# MB9BF12xT register map
File version: 1.0
CPU: 
Registers are 8-bit, read-write, reset 0x0 unless marked. A register's access mark holds for its fields unless they carry their own. Offsets are from the block's base; [hi:lo] are bit positions; {n}, {i} and the like mark numbered series.

## HDMICEC0 — peripheral HDMICEC0
Base 0x40034000
Same registers: HDMICEC1 0x40034100
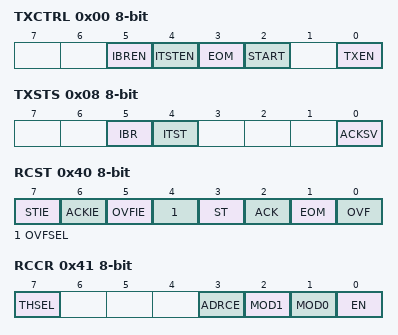
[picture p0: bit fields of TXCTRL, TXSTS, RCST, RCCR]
0x00 TXCTRL
  [5] IBREN, [4] ITSTEN, [3] EOM, [2] START, [0] TXEN
0x04 TXDATA
0x08 TXSTS
  [5] IBR, [4] ITST, [0] ACKSV
0x0C SFREE
  [3:0] SFREE
0x40 RCST
  [7] STIE, [6] ACKIE, [5] OVFIE, [4] OVFSEL, [3] ST, [2] ACK, [1] EOM, [0] OVF
0x41 RCCR
  [7] THSEL, [3] ADRCE, [2] MOD1, [1] MOD0, [0] EN
0x44 RCDAHW
0x45 RCSHW
0x49 RCDBHW
0x4C RCADR2
  [4:0] RCADR2
0x4D RCADR1
  [4:0] RCADR1
0x50 RCDTHL ro
0x51 RCDTHH ro
0x54 RCDTLL ro
0x55 RCDTLH ro
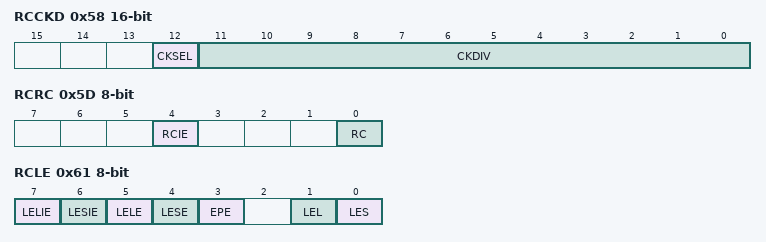
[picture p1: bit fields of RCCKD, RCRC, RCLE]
0x58 RCCKD 16-bit
  [12] CKSEL, [11:0] CKDIV
0x5C RCRHW
0x5D RCRC
  [4] RCIE, [0] RC
0x61 RCLE
  [7] LELIE, [6] LESIE, [5] LELE, [4] LESE, [3] EPE, [1] LEL, [0] LES
0x64 RCLESW
0x65 RCLELW

## LVD — peripheral LVD
Base 0x40035000
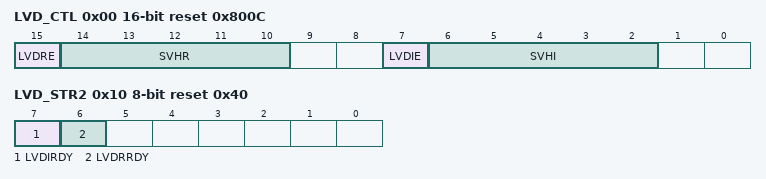
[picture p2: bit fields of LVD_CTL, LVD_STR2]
0x00 LVD_CTL 16-bit reset 0x800C
  [15] LVDRE, [14:10] SVHR, [7] LVDIE, [6:2] SVHI
0x04 LVD_STR ro
  [7] LVDIR
0x08 LVD_CLR reset 0x80
  [7] LVDCL
0x0C LVD_RLR 32-bit reset 0x1
  [31:0] LVDLCK
0x10 LVD_STR2 ro reset 0x40
  [7] LVDIRDY, [6] LVDRRDY

## DS — peripheral DS
Base 0x40035100
0x00 REG_CTL reset 0x4
  [2:1] ISUBSEL
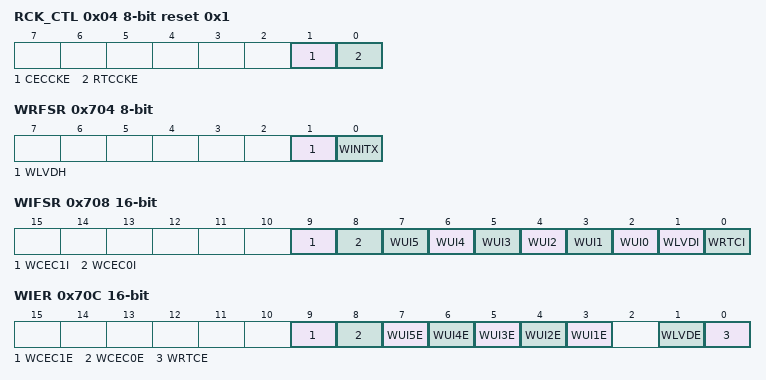
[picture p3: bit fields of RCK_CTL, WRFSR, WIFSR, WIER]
0x04 RCK_CTL reset 0x1
  [1] CECCKE, [0] RTCCKE
0x700 PMD_CTL
  [0] RTCE
0x704 WRFSR
  [1] WLVDH, [0] WINITX
0x708 WIFSR 16-bit ro
  [9] WCEC1I, [8] WCEC0I, [n+2] WUI{n} (n=0..5), [1] WLVDI, [0] WRTCI
0x70C WIER 16-bit
  [9] WCEC1E, [8] WCEC0E, [n+2] WUI{n}E (n=1..5), [1] WLVDE, [0] WRTCE
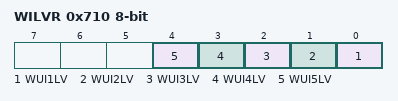
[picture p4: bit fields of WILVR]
0x710 WILVR
  [n-1] WUI{n}LV (n=1..5)
0x714 DSRAMR
  [1:0] SRAMR
{0x7FF+i} BUR{i:02} (i=1..16)

## MFS0 — peripheral MFS0
Base 0x40038000
Same registers: MFS{n} {0x40038000+0x100*n} (n=1..15)
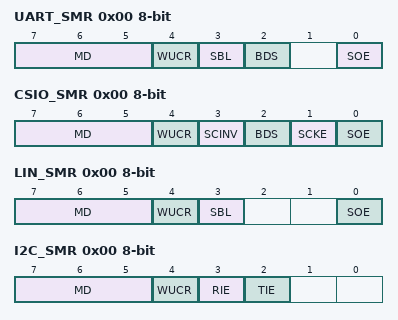
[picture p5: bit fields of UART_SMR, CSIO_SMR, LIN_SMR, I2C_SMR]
0x00 UART_SMR (UART view)
  [7:5] MD, [4] WUCR, [3] SBL, [2] BDS, [0] SOE
0x00 CSIO_SMR (CSIO view)
  [7:5] MD, [4] WUCR, [3] SCINV, [2] BDS, [1] SCKE, [0] SOE
0x00 LIN_SMR (LIN view)
  [7:5] MD, [4] WUCR, [3] SBL, [0] SOE
0x00 I2C_SMR (I2C view)
  [7:5] MD, [4] WUCR, [3] RIE, [2] TIE
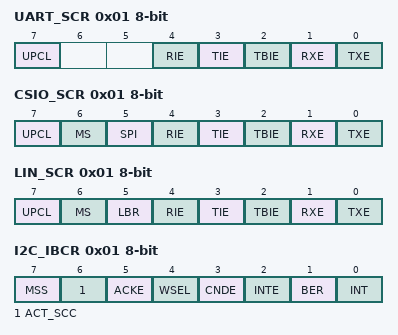
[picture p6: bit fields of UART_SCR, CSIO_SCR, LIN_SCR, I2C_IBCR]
0x01 UART_SCR (UART view)
  [7] UPCL, [4] RIE, [3] TIE, [2] TBIE, [1] RXE, [0] TXE
0x01 CSIO_SCR (CSIO view)
  [7] UPCL, [6] MS, [5] SPI, [4] RIE, [3] TIE, [2] TBIE, [1] RXE, [0] TXE
0x01 LIN_SCR (LIN view)
  [7] UPCL, [6] MS, [5] LBR, [4] RIE, [3] TIE, [2] TBIE, [1] RXE, [0] TXE
0x01 I2C_IBCR (I2C view)
  [7] MSS, [6] ACT_SCC, [5] ACKE, [4] WSEL, [3] CNDE, [2] INTE, [1] BER ro, [0] INT
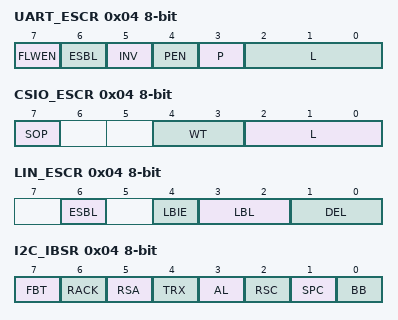
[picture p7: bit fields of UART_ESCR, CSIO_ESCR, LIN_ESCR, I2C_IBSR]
0x04 UART_ESCR (UART view)
  [7] FLWEN, [6] ESBL, [5] INV, [4] PEN, [3] P, [2:0] L
0x04 CSIO_ESCR (CSIO view)
  [7] SOP, [4:3] WT, [2:0] L
0x04 LIN_ESCR (LIN view)
  [6] ESBL, [4] LBIE, [3:2] LBL, [1:0] DEL
0x04 I2C_IBSR (I2C view)
  [7] FBT ro, [6] RACK ro, [5] RSA ro, [4] TRX ro, [3] AL ro, [2] RSC, [1] SPC, [0] BB ro
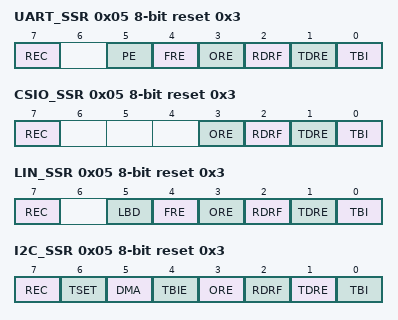
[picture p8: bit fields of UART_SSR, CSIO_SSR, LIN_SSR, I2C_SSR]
0x05 UART_SSR reset 0x3 (UART view)
  [7] REC, [5] PE ro, [4] FRE ro, [3] ORE ro, [2] RDRF ro, [1] TDRE ro, [0] TBI ro
0x05 CSIO_SSR reset 0x3 (CSIO view)
  [7] REC, [3] ORE ro, [2] RDRF ro, [1] TDRE ro, [0] TBI ro
0x05 LIN_SSR reset 0x3 (LIN view)
  [7] REC, [5] LBD, [4] FRE ro, [3] ORE ro, [2] RDRF ro, [1] TDRE ro, [0] TBI ro
0x05 I2C_SSR reset 0x3 (I2C view)
  [7] REC, [6] TSET, [5] DMA, [4] TBIE, [3] ORE ro, [2] RDRF ro, [1] TDRE ro, [0] TBI ro
0x08 UART_RDR 16-bit ro (reset mask 0x1FF) (UART view)
0x08 UART_TDR 16-bit wo reset 0x1FF (reset mask 0x1FF) (UART view)
0x08 CSIO_RDR 16-bit ro (reset mask 0x1FF) (CSIO view)
0x08 CSIO_TDR 16-bit wo reset 0x1FF (reset mask 0x1FF) (CSIO view)
0x08 LIN_RDR 16-bit ro (reset mask 0xFF) (LIN view)
0x08 LIN_TDR 16-bit wo reset 0xFF (reset mask 0xFF) (LIN view)
0x08 I2C_RDR 16-bit ro (reset mask 0xFF) (I2C view)
0x08 I2C_TDR 16-bit wo reset 0xFF (reset mask 0xFF) (I2C view)
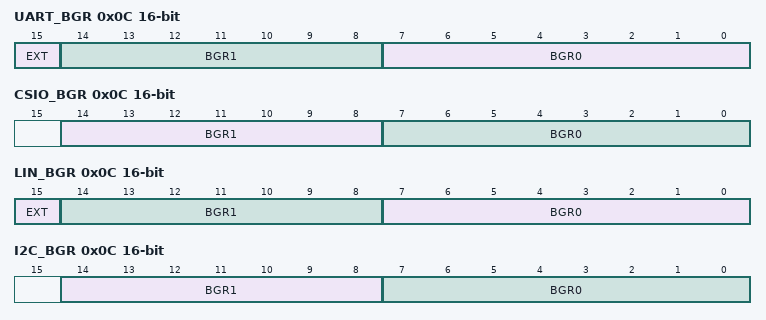
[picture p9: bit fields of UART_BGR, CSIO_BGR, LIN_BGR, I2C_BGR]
0x0C UART_BGR 16-bit (UART view)
  [15] EXT, [14:8] BGR1, [7:0] BGR0
0x0C CSIO_BGR 16-bit (CSIO view)
  [14:8] BGR1, [7:0] BGR0
0x0C LIN_BGR 16-bit (LIN view)
  [15] EXT, [14:8] BGR1, [7:0] BGR0
0x0C I2C_BGR 16-bit (I2C view)
  [14:8] BGR1, [7:0] BGR0
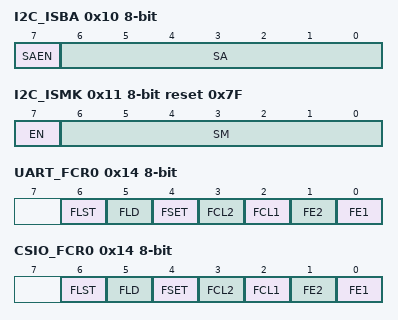
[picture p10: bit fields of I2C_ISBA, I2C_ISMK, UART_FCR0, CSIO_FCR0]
0x10 I2C_ISBA (I2C view)
  [7] SAEN, [6:0] SA
0x11 I2C_ISMK reset 0x7F (I2C view)
  [7] EN, [6:0] SM
0x14 UART_FCR0 (UART view)
  [6] FLST ro, [5] FLD, [4] FSET, [3] FCL2, [2] FCL1, [1] FE2, [0] FE1
0x14 CSIO_FCR0 (CSIO view)
  [6] FLST ro, [5] FLD, [4] FSET, [3] FCL2, [2] FCL1, [1] FE2, [0] FE1
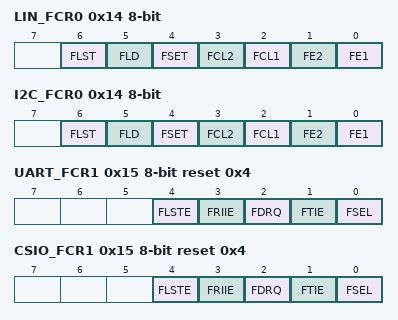
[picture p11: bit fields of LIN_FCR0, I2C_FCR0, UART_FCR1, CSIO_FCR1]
0x14 LIN_FCR0 (LIN view)
  [6] FLST ro, [5] FLD, [4] FSET, [3] FCL2, [2] FCL1, [1] FE2, [0] FE1
0x14 I2C_FCR0 (I2C view)
  [6] FLST ro, [5] FLD, [4] FSET, [3] FCL2, [2] FCL1, [1] FE2, [0] FE1
0x15 UART_FCR1 reset 0x4 (UART view)
  [4] FLSTE, [3] FRIIE, [2] FDRQ, [1] FTIE, [0] FSEL
0x15 CSIO_FCR1 reset 0x4 (CSIO view)
  [4] FLSTE, [3] FRIIE, [2] FDRQ, [1] FTIE, [0] FSEL
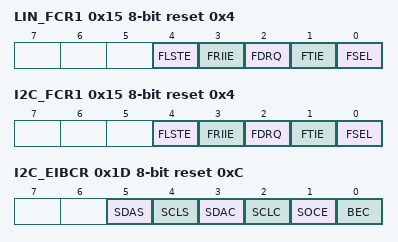
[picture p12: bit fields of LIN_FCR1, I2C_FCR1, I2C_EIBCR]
0x15 LIN_FCR1 reset 0x4 (LIN view)
  [4] FLSTE, [3] FRIIE, [2] FDRQ, [1] FTIE, [0] FSEL
0x15 I2C_FCR1 reset 0x4 (I2C view)
  [4] FLSTE, [3] FRIIE, [2] FDRQ, [1] FTIE, [0] FSEL
0x18 UART_FBYTE1 (UART view)
0x18 CSIO_FBYTE1 (CSIO view)
0x18 LIN_FBYTE1 (LIN view)
0x18 I2C_FBYTE1 (I2C view)
0x19 UART_FBYTE2 (UART view)
0x19 CSIO_FBYTE2 (CSIO view)
0x19 LIN_FBYTE2 (LIN view)
0x19 I2C_FBYTE2 (I2C view)
0x1D I2C_EIBCR reset 0xC (I2C view)
  [5] SDAS, [4] SCLS, [3] SDAC, [2] SCLC, [1] SOCE, [0] BEC

## RTC — peripheral RTC
Base 0x4003B000
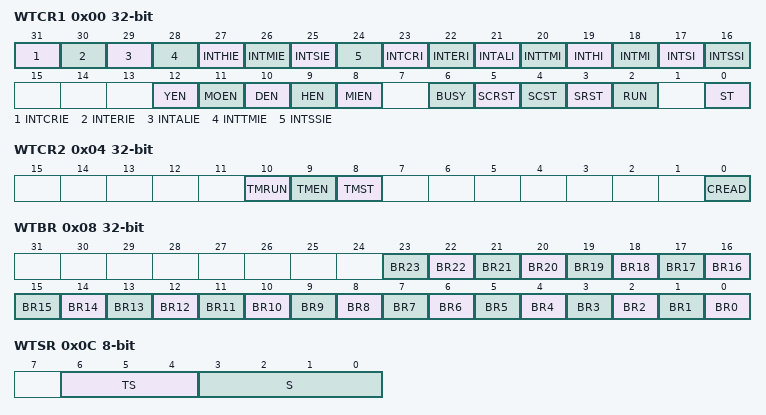
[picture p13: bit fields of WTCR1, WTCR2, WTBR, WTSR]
0x00 WTCR1 32-bit
  [31] INTCRIE, [30] INTERIE, [29] INTALIE, [28] INTTMIE, [27] INTHIE, [26] INTMIE, [25] INTSIE, [24] INTSSIE, [23] INTCRI, [22] INTERI, [21] INTALI, [20] INTTMI, [19] INTHI, [18] INTMI, [17] INTSI, [16] INTSSI, [12] YEN, [11] MOEN, [10] DEN, [9] HEN, [8] MIEN, [6] BUSY ro, [5] SCRST, [4] SCST, [3] SRST, [2] RUN ro, [0] ST
0x04 WTCR2 32-bit
  [10] TMRUN ro, [9] TMEN, [8] TMST, [0] CREAD
0x08 WTBR 32-bit
  [n] BR{n} (n=0..23)
0x0C WTSR
  [6:4] TS, [3:0] S
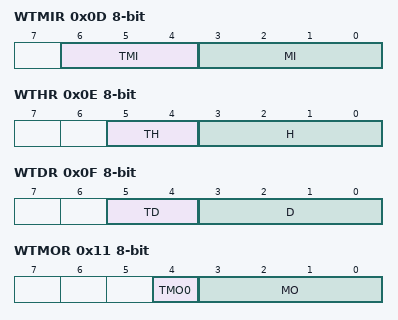
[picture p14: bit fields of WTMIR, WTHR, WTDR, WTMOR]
0x0D WTMIR
  [6:4] TMI, [3:0] MI
0x0E WTHR
  [5:4] TH, [3:0] H
0x0F WTDR
  [5:4] TD, [3:0] D
0x10 WTDW
  [2:0] DW
0x11 WTMOR
  [4] TMO0, [3:0] MO
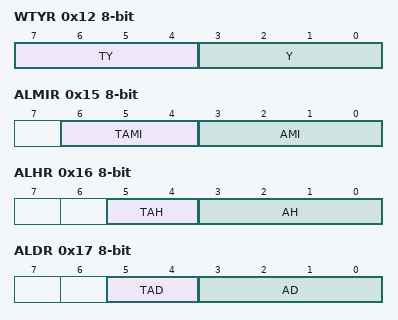
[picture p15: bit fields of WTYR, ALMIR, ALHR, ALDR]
0x12 WTYR
  [7:4] TY, [3:0] Y
0x15 ALMIR
  [6:4] TAMI, [3:0] AMI
0x16 ALHR
  [5:4] TAH, [3:0] AH
0x17 ALDR
  [5:4] TAD, [3:0] AD
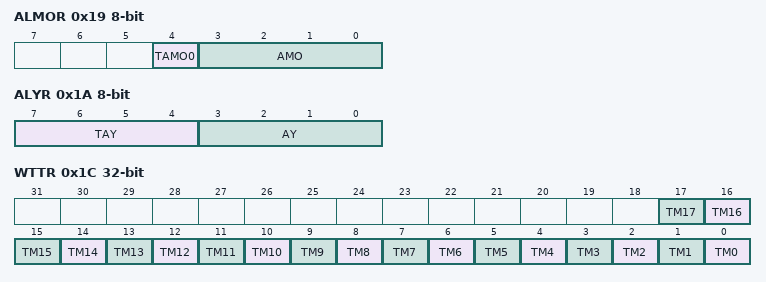
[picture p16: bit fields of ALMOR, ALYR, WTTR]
0x19 ALMOR
  [4] TAMO0, [3:0] AMO
0x1A ALYR
  [7:4] TAY, [3:0] AY
0x1C WTTR 32-bit
  [n] TM{n} (n=0..17)
0x20 WTCLKS
  [0] WTCLKS
0x21 WTCLKM ro
  [1:0] WTCLKM
0x24 WTCAL 16-bit
  [9:0] WTCAL
0x26 WTCALEN
  [0] WTCALEN
0x28 WTDIV
  [3:0] WTDIV
0x29 WTDIVEN
  [1] WTDIVRDY ro, [0] WTDIVEN
0x2C WTCALPRD reset 0x13
  [5:0] WTCALPRD
0x30 WTCOSEL
  [0] WTCOSEL

## CRC — peripheral CRC
Base 0x40039000
0x00 CRCCR
  [6] FXOR, [5] CRCLSF, [4] CRCLTE, [3] LSBFST, [2] LTLEND, [1] CRC32, [0] INIT
0x04 CRCINIT 32-bit reset 0xFFFFFFFF
  [31:0] D
0x08 CRCIN 32-bit
  [31:0] D
0x0C CRCR 32-bit ro reset 0xFFFFFFFF
  [31:0] D

## EXBUS — peripheral EXBUS
Base 0x4003F000
0x00 MODE0 32-bit
  [13] MOEXEUP, [12] MPXCSOF, [11] MPXDOFF, [9] ALEINV, [8] MPXMODE, [7] SHRTDOUT, [6] RDY, [5] PAGE, [4] NAND, [3] WEOFF, [2] RBMON, [1:0] WDTH
{0x0+4i} MODE{i} 32-bit reset not defined (i=1..7)
0x20 TIM0 32-bit reset 0x55FF00F
  [31:28] WIDLC, [27:24] WWEC, [23:20] WADC, [19:16] WACC, [15:12] RIDLC, [11:8] FRADC, [7:4] RADC, [3:0] RACC
{0x20+4i} TIM{i} 32-bit reset not defined (i=1..7)
0x40 AREA0 32-bit reset 0xF0000
  [22:16] MASK, [7:0] ADDR
0x44 AREA1 32-bit reset 0xF0010
  [22:16] MASK, [7:0] ADDR
0x48 AREA2 32-bit reset 0xF0020
  [22:16] MASK, [7:0] ADDR
0x4C AREA3 32-bit reset 0xF0030
  [22:16] MASK, [7:0] ADDR
0x50 AREA4 32-bit reset 0xF0040
  [22:16] MASK, [7:0] ADDR
0x54 AREA5 32-bit reset 0xF0050
  [22:16] MASK, [7:0] ADDR
0x58 AREA6 32-bit reset 0xF0060
  [22:16] MASK, [7:0] ADDR
0x5C AREA7 32-bit reset 0xF0070
  [22:16] MASK, [7:0] ADDR
0x60 ATIM0 32-bit reset 0x45F
  [11:8] ALEW, [7:4] ALES, [3:0] ALC
{0x60+4i} ATIM{i} 32-bit reset not defined (i=1..7)
0x300 DCLKR 32-bit reset 0x1 (reset mask 0xF)
  [4] MCLKON, [3:0] MDIV

## DMAC — peripheral DMAC
Base 0x40060000
0x00 DMACR 32-bit
  [31] DE, [30] DS, [28] PR, [27:24] DH
0x10 DMACA0 32-bit
  [31] EB, [30] PB, [29] ST, [28:23] IS, [19:16] BC, [15:0] TC
0x14 DMACB0 32-bit
  [29:28] MS, [27:26] TW, [25] FS, [24] FD, [23] RC, [22] RS, [21] RD, [20] EI, [19] CI, [18:16] SS, [0] EM
0x18 DMACSA0 32-bit
0x1C DMACDA0 32-bit
{0x10+0x10*i} DMACA{i} 32-bit reset not defined (i=1..7)
{0x14+0x10*i} DMACB{i} 32-bit reset not defined (i=1..7)
{0x18+0x10*i} DMACSA{i} 32-bit reset not defined (i=1..7)
{0x1C+0x10*i} DMACDA{i} 32-bit reset not defined (i=1..7)
